# ATSAME53J19A register map
Vendor: Microchip Technology Inc.; Series: SAME53; File version: A
CPU: CM4 r0p1, little endian, MPU, FPU, 3 interrupt priority bits, 137 interrupts
Registers are 32-bit, read-write, reset 0x0 unless marked. A register's access mark holds for its fields unless they carry their own. Offsets are from the block's base; [hi:lo] are bit positions; {n}, {i} and the like mark numbered series; 'fields as' and 'values as' point back to an identical list.

## OSCCTRL — Oscillators Control
Base 0x40001000; register names take the prefix OSCCTRL_
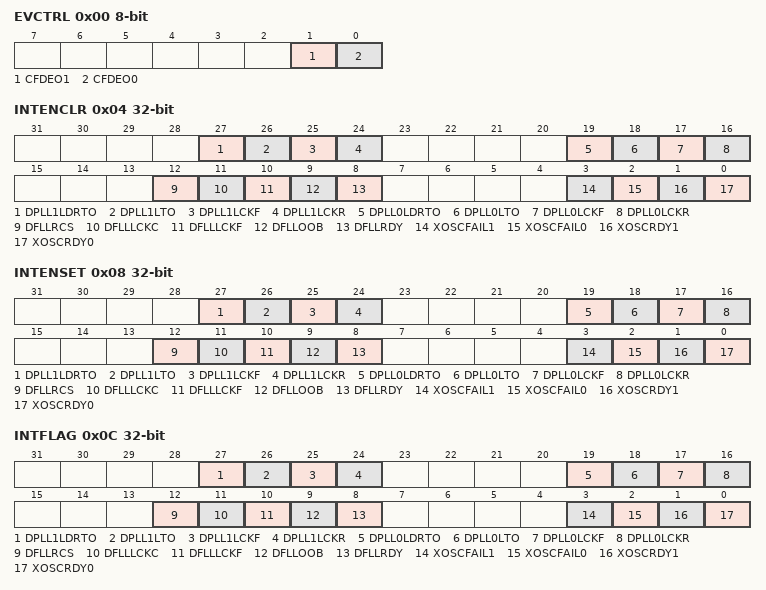
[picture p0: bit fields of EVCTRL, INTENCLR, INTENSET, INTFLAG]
0x00 EVCTRL 8-bit — Event Control
  [1] CFDEO1 — Clock 1 Failure Detector Event Output Enable
  [0] CFDEO0 — Clock 0 Failure Detector Event Output Enable
0x04 INTENCLR — Interrupt Enable Clear
  [27] DPLL1LDRTO — DPLL1 Loop Divider Ratio Update Complete Interrupt Enable
  [26] DPLL1LTO — DPLL1 Lock Timeout Interrupt Enable
  [25] DPLL1LCKF — DPLL1 Lock Fall Interrupt Enable
  [24] DPLL1LCKR — DPLL1 Lock Rise Interrupt Enable
  [19] DPLL0LDRTO — DPLL0 Loop Divider Ratio Update Complete Interrupt Enable
  [18] DPLL0LTO — DPLL0 Lock Timeout Interrupt Enable
  [17] DPLL0LCKF — DPLL0 Lock Fall Interrupt Enable
  [16] DPLL0LCKR — DPLL0 Lock Rise Interrupt Enable
  [12] DFLLRCS — DFLL Reference Clock Stopped Interrupt Enable
  [11] DFLLLCKC — DFLL Lock Coarse Interrupt Enable
  [10] DFLLLCKF — DFLL Lock Fine Interrupt Enable
  [9] DFLLOOB — DFLL Out Of Bounds Interrupt Enable
  [8] DFLLRDY — DFLL Ready Interrupt Enable
  [3] XOSCFAIL1 — XOSC 1 Clock Failure Detector Interrupt Enable
  [2] XOSCFAIL0 — XOSC 0 Clock Failure Detector Interrupt Enable
  [1] XOSCRDY1 — XOSC 1 Ready Interrupt Enable
  [0] XOSCRDY0 — XOSC 0 Ready Interrupt Enable
0x08 INTENSET — Interrupt Enable Set
  fields as INTENCLR
0x0C INTFLAG — Interrupt Flag Status and Clear
  [27] DPLL1LDRTO — DPLL1 Loop Divider Ratio Update Complete
  [26] DPLL1LTO — DPLL1 Lock Timeout
  [25] DPLL1LCKF — DPLL1 Lock Fall
  [24] DPLL1LCKR — DPLL1 Lock Rise
  [19] DPLL0LDRTO — DPLL0 Loop Divider Ratio Update Complete
  [18] DPLL0LTO — DPLL0 Lock Timeout
  [17] DPLL0LCKF — DPLL0 Lock Fall
  [16] DPLL0LCKR — DPLL0 Lock Rise
  [12] DFLLRCS — DFLL Reference Clock Stopped
  [11] DFLLLCKC — DFLL Lock Coarse
  [10] DFLLLCKF — DFLL Lock Fine
  [9] DFLLOOB — DFLL Out Of Bounds
  [8] DFLLRDY — DFLL Ready
  [3] XOSCFAIL1 — XOSC 1 Clock Failure Detector
  [2] XOSCFAIL0 — XOSC 0 Clock Failure Detector
  [1] XOSCRDY1 — XOSC 1 Ready
  [0] XOSCRDY0 — XOSC 0 Ready
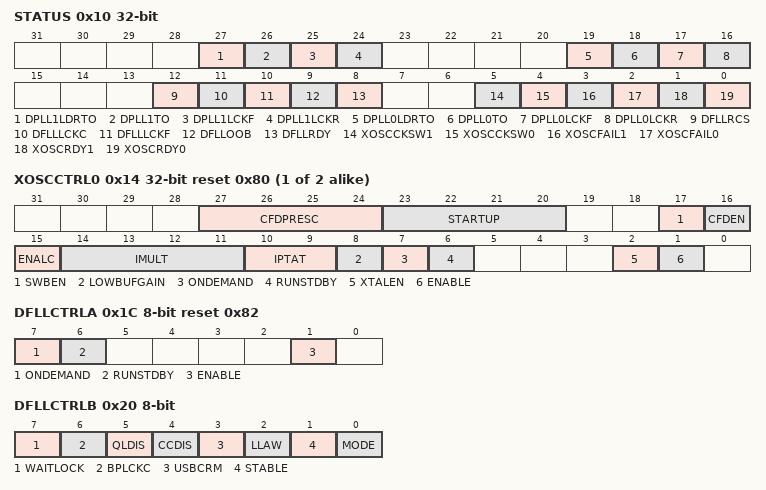
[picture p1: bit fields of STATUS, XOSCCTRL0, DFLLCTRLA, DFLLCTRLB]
0x10 STATUS ro
  [27] DPLL1LDRTO — DPLL1 Loop Divider Ratio Update Complete
  [26] DPLL1TO — DPLL1 Timeout
  [25] DPLL1LCKF — DPLL1 Lock Fall
  [24] DPLL1LCKR — DPLL1 Lock Rise
  [19] DPLL0LDRTO — DPLL0 Loop Divider Ratio Update Complete
  [18] DPLL0TO — DPLL0 Timeout
  [17] DPLL0LCKF — DPLL0 Lock Fall
  [16] DPLL0LCKR — DPLL0 Lock Rise
  [12] DFLLRCS — DFLL Reference Clock Stopped
  [11] DFLLLCKC — DFLL Lock Coarse
  [10] DFLLLCKF — DFLL Lock Fine
  [9] DFLLOOB — DFLL Out Of Bounds
  [8] DFLLRDY — DFLL Ready
  [5] XOSCCKSW1 — XOSC 1 Clock Switch
  [4] XOSCCKSW0 — XOSC 0 Clock Switch
  [3] XOSCFAIL1 — XOSC 1 Clock Failure Detector
  [2] XOSCFAIL0 — XOSC 0 Clock Failure Detector
  [1] XOSCRDY1 — XOSC 1 Ready
  [0] XOSCRDY0 — XOSC 0 Ready
{0x14+4i} XOSCCTRL{i} (i=0..1) reset 0x80 — External Multipurpose Crystal Oscillator Control
  [27:24] CFDPRESC — Clock Failure Detector Prescaler
  [23:20] STARTUP — Start-Up Time
  [17] SWBEN — Xosc Clock Switch Enable
  [16] CFDEN — Clock Failure Detector Enable
  [15] ENALC — Automatic Loop Control Enable
  [14:11] IMULT — Oscillator Current Multiplier
  [10:9] IPTAT — Oscillator Current Reference
  [8] LOWBUFGAIN — Low Buffer Gain Enable
  [7] ONDEMAND — On Demand Control
  [6] RUNSTDBY — Run in Standby
  [2] XTALEN — Crystal Oscillator Enable
  [1] ENABLE — Oscillator Enable
0x1C DFLLCTRLA 8-bit reset 0x82 — DFLL48M Control A
  [7] ONDEMAND — On Demand Control
  [6] RUNSTDBY — Run in Standby
  [1] ENABLE — DFLL Enable
0x20 DFLLCTRLB 8-bit — DFLL48M Control B
  [7] WAITLOCK
  [6] BPLCKC — Bypass Coarse Lock
  [5] QLDIS — Quick Lock Disable
  [4] CCDIS — Chill Cycle Disable
  [3] USBCRM — USB Clock Recovery Mode
  [2] LLAW — Lose Lock After Wake
  [1] STABLE — Stable DFLL Frequency
  [0] MODE — Operating Mode Selection
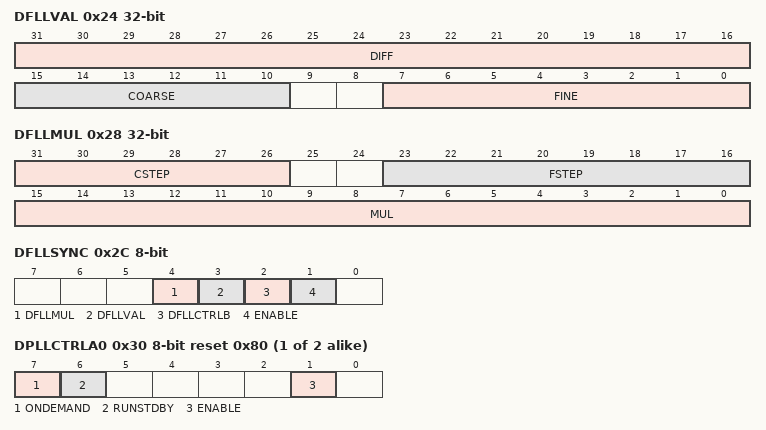
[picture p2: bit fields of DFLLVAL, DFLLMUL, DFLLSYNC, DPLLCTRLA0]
0x24 DFLLVAL — DFLL48M Value
  [31:16] DIFF ro — Multiplication Ratio Difference
  [15:10] COARSE — Coarse Value
  [7:0] FINE — Fine Value
0x28 DFLLMUL — DFLL48M Multiplier
  [31:26] CSTEP — Coarse Maximum Step
  [23:16] FSTEP — Fine Maximum Step
  [15:0] MUL — DFLL Multiply Factor
0x2C DFLLSYNC 8-bit — DFLL48M Synchronization
  [4] DFLLMUL ro — DFLLMUL Synchronization Busy
  [3] DFLLVAL ro — DFLLVAL Synchronization Busy
  [2] DFLLCTRLB ro — DFLLCTRLB Synchronization Busy
  [1] ENABLE ro — ENABLE Synchronization Busy
{0x30+0x14*i} DPLLCTRLA{i} (i=0..1) 8-bit reset 0x80 — DPLL Control A
  [7] ONDEMAND — On Demand Control
  [6] RUNSTDBY — Run in Standby
  [1] ENABLE — DPLL Enable
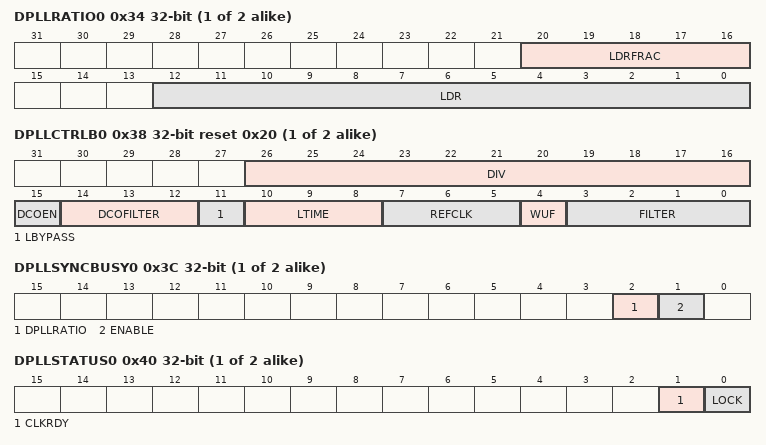
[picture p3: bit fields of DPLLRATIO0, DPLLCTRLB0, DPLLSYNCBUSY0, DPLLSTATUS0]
{0x34+0x14*i} DPLLRATIO{i} (i=0..1) — DPLL Ratio Control
  [20:16] LDRFRAC — Loop Divider Ratio Fractional Part
  [12:0] LDR — Loop Divider Ratio
{0x38+0x14*i} DPLLCTRLB{i} (i=0..1) reset 0x20 — DPLL Control B
  [26:16] DIV — Clock Divider
  [15] DCOEN — DCO Filter Enable
  [14:12] DCOFILTER — Sigma-Delta DCO Filter Selection
  [11] LBYPASS — Lock Bypass
  [10:8] LTIME — Lock Time
    0=DEFAULT (No time-out. Automatic lock); 4=800US (Time-out if no lock within 800us); 5=900US (Time-out if no lock within 900us); 6=1MS (Time-out if no lock within 1ms); 7=1P1MS (Time-out if no lock within 1.1ms)
  [7:5] REFCLK — Reference Clock Selection
    0=GCLK (Dedicated GCLK clock reference); 1=XOSC32 (XOSC32K clock reference); 2=XOSC0 (XOSC0 clock reference); 3=XOSC1 (XOSC1 clock reference)
  [4] WUF — Wake Up Fast
  [3:0] FILTER — Proportional Integral Filter Selection
{0x3C+0x14*i} DPLLSYNCBUSY{i} (i=0..1) ro — DPLL Synchronization Busy
  [2] DPLLRATIO — DPLL Loop Divider Ratio Synchronization Status
  [1] ENABLE — DPLL Enable Synchronization Status
{0x40+0x14*i} DPLLSTATUS{i} (i=0..1) ro
  [1] CLKRDY — DPLL Clock Ready
  [0] LOCK — DPLL Lock Status

## Notices in the file
Copyright (c) 2018 Microchip Technology Inc.
SPDX-License-Identifier: Apache-2.0
Licensed under the Apache License, Version 2.0 (the "License");
you may not use this file except in compliance with the License.
You may obtain a copy of the License at
http://www.apache.org/licenses/LICENSE-2.0
Unless required by applicable law or agreed to in writing, software
distributed under the License is distributed on an "AS IS" BASIS,
WITHOUT WARRANTIES OR CONDITIONS OF ANY KIND, either express or implied.
See the License for the specific language governing permissions and
limitations under the License.
